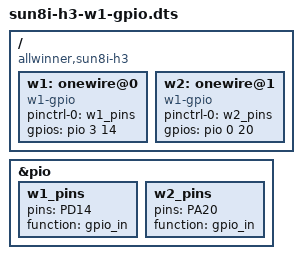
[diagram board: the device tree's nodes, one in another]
/dts-v1/;
/plugin/;

/ {
	compatible = "allwinner,sun8i-h3";

	fragment@0 {
		target = <&pio>;
		__overlay__ {
			w1_pins: w1_pins {
				pins = "PD14";
				function = "gpio_in";
			};
			w2_pins: w2_pins {
				pins = "PA20";
				function = "gpio_in";
			};
		};
	};

	fragment@1 {
		target-path = "/";
		__overlay__ {
			w1: onewire@0 {
				compatible = "w1-gpio";
				pinctrl-names = "default";
				pinctrl-0 = <&w1_pins>;
				////gpios = <&pio 3 14 0>; /* PD14 */
				gpios = <&pio 3 14 0>; /* PD14  PA20*/
				status = "okay";
			};
            //added by TD
			w2: onewire@1 {
				compatible = "w1-gpio";
				pinctrl-names = "default";
				pinctrl-0 = <&w2_pins>;
				////gpios = <&pio 3 14 0>; /* PD14 */
				gpios = <&pio 0 20 0>; /* PD14  PA20*/
				status = "okay";
			};
		};
	};
    __overrides__ {
                    gpiopin =       <&w1>,"gpios:3 14",
                                    <&w1_pins>,"allwinner,pins:0";
                    gpiopin1 =      <&w2>,"gpios:0 20",
                                    <&w2_pins>,"allwinner,pins:0";
            };

};
